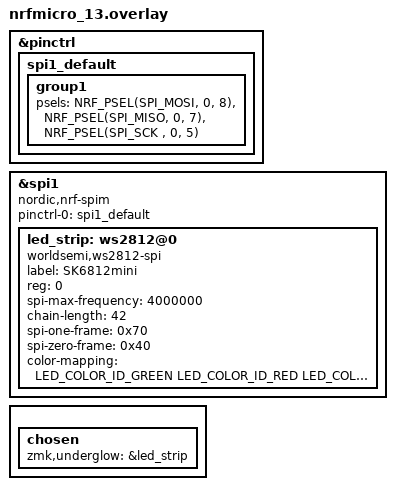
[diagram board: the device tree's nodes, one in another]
&pinctrl {
    spi1_default: spi1_default {
        group1 {
            psels =
                <NRF_PSEL(SPI_MOSI, 0, 8)>,
                <NRF_PSEL(SPI_MISO, 0, 7)>,
                <NRF_PSEL(SPI_SCK , 0, 5)>;
        };
    };
};

&spi1 {
    compatible = "nordic,nrf-spim";
    status = "okay";

    pinctrl-0 = <&spi1_default>;
    pinctrl-names = "default";

    led_strip: ws2812@0 {
        compatible = "worldsemi,ws2812-spi";
        label = "SK6812mini";
        reg = <0>;
        spi-max-frequency = <4000000>;
        chain-length = <42>;
        spi-one-frame  = <0x70>;
        spi-zero-frame = <0x40>;
        color-mapping = <
            LED_COLOR_ID_GREEN
            LED_COLOR_ID_RED
            LED_COLOR_ID_BLUE
        >;
    };
};

{
    chosen {
        zmk,underglow = &led_strip;
    };
};
